VERSION ""

NS_ :

BS_:

BU_: HCU BMS MCU

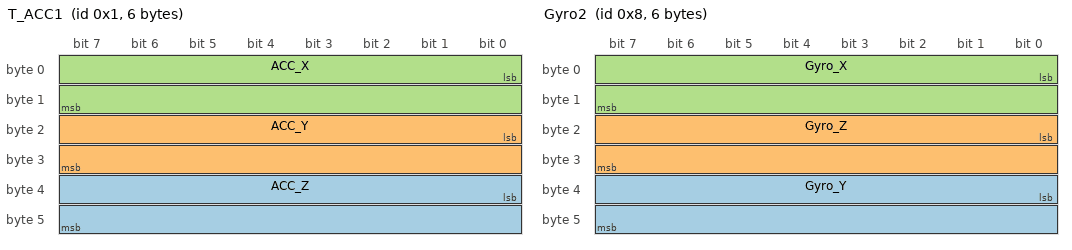
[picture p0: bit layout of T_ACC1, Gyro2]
BO_ 1 T_ACC1: 6 Vector__XXX
 SG_ ACC_Z : 32|16@1- (0.01,-25) [0|0] "g" Vector__XXX
 SG_ ACC_Y : 16|16@1- (0.01,-25) [0|0] "g" Vector__XXX
 SG_ ACC_X : 0|16@1- (0.01,-25) [0|0] "g" Vector__XXX

BO_ 8 Gyro2: 6 Vector__XXX
 SG_ Gyro_Y : 32|16@1- (0.05,-819.15) [0|0] "deg/sec" Vector__XXX
 SG_ Gyro_Z : 16|16@1- (0.05,-819.15) [0|0] "deg/sec" Vector__XXX
 SG_ Gyro_X : 0|16@1- (0.05,-819.15) [0|0] "deg/sec" Vector__XXX

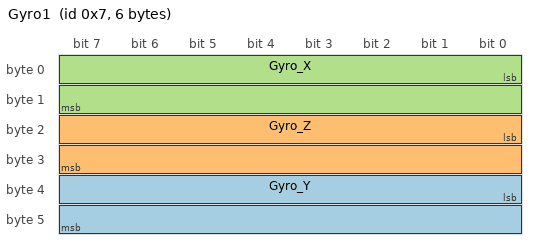
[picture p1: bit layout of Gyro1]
BO_ 7 Gyro1: 6 BMS
 SG_ Gyro_Y : 32|16@1- (0.05,-819.15) [0|0] "deg/sec" Vector__XXX
 SG_ Gyro_Z : 16|16@1- (0.05,-819.15) [0|0] "deg/sec" Vector__XXX
 SG_ Gyro_X : 0|16@1- (0.05,-819.15) [0|0] "deg/sec" Vector__XXX

BA_DEF_ SG_  "GenSigEnvVarType" ENUM  "int","float","undef";
BA_DEF_ SG_  "GenSigSendType" ENUM  "Cyclic","OnWrite","OnWriteWithRepetition","OnChange","OnChangeWithRepetition","IfActive","IfActiveWithRepetition";
BA_DEF_ BO_  "GenMsgDelayTime" INT 1 1000;
BA_DEF_ BO_  "GenMsgCycleTime" INT 2 50000;
BA_DEF_ BO_  "GenMsgSendType" ENUM  "Cyclic","not_used","not_used","not_used","not_used","Cyclic","not_used","IfActive";
BA_DEF_ BO_  "GenMsgCycleTimeFast" INT 2 100000;
BA_DEF_ BO_  "GenMsgILSupport" ENUM  "No","Yes";
BA_DEF_ BU_  "TpNodeBaseAddress" HEX 0 33554431;
BA_DEF_ BU_  "TpUseFC" INT 0 1;
BA_DEF_ BU_  "TpCanBus" INT 1 2;
BA_DEF_ BU_  "TpRxMask" HEX 0 65535;
BA_DEF_ BU_  "TpRxIdentifier" HEX 0 536870911;
BA_DEF_ BU_  "TpTxIdentifier" HEX 0 536870911;
BA_DEF_ BU_  "ILUsed" ENUM  "Yes","No";
BA_DEF_ BU_  "TpAddressingMode" INT 0 3;
BA_DEF_  "GenNWMTalkNM" STRING ;
BA_DEF_  "GenNWMGotoMode_BusSleep" STRING ;
BA_DEF_  "GenNWMGotoMode_Awake" STRING ;
BA_DEF_  "GenNWMApCanSleep" STRING ;
BA_DEF_  "GenNWMApCanOn" STRING ;
BA_DEF_  "GenNWMApCanOff" STRING ;
BA_DEF_  "NmBaseAddress" HEX 1024 1055;
BA_DEF_  "GenEnvVarPrefix" STRING ;
BA_DEF_  "GenEnvVarEndingSnd" STRING ;
BA_DEF_  "GenEnvVarEndingDsp" STRING ;
BA_DEF_  "DBName" STRING ;
BA_DEF_DEF_  "GenSigEnvVarType" "undef";
BA_DEF_DEF_  "GenSigSendType" "Cyclic";
BA_DEF_DEF_  "GenMsgDelayTime" 1;
BA_DEF_DEF_  "GenMsgCycleTime" 2;
BA_DEF_DEF_  "GenMsgSendType" "not_used";
BA_DEF_DEF_  "GenMsgCycleTimeFast" 100;
BA_DEF_DEF_  "GenMsgILSupport" "Yes";
BA_DEF_DEF_  "TpNodeBaseAddress" 1536;
BA_DEF_DEF_  "TpUseFC" 1;
BA_DEF_DEF_  "TpCanBus" 1;
BA_DEF_DEF_  "TpRxMask" 255;
BA_DEF_DEF_  "TpRxIdentifier" 1;
BA_DEF_DEF_  "TpTxIdentifier" 1;
BA_DEF_DEF_  "ILUsed" "Yes";
BA_DEF_DEF_  "TpAddressingMode" 1;
BA_DEF_DEF_  "GenNWMTalkNM" "TalkNM()";
BA_DEF_DEF_  "GenNWMGotoMode_BusSleep" "GotoMode_BusSleep()";
BA_DEF_DEF_  "GenNWMGotoMode_Awake" "GotoMode_Awake()";
BA_DEF_DEF_  "GenNWMApCanSleep" "apCanSleep()";
BA_DEF_DEF_  "GenNWMApCanOn" "apCanOn()";
BA_DEF_DEF_  "GenNWMApCanOff" "apCanOff()";
BA_DEF_DEF_  "NmBaseAddress" 1024;
BA_DEF_DEF_  "GenEnvVarPrefix" "Env";
BA_DEF_DEF_  "GenEnvVarEndingSnd" "_";
BA_DEF_DEF_  "GenEnvVarEndingDsp" "Dsp_";
BA_DEF_DEF_  "DBName" "";
BA_ "DBName" "ACC_CAN";
BA_ "GenMsgCycleTime" BO_ 1 20;
BA_ "GenMsgSendType" BO_ 1 0;
BA_ "GenMsgCycleTime" BO_ 8 10;
BA_ "GenMsgSendType" BO_ 8 0;
BA_ "GenMsgCycleTime" BO_ 7 10;
BA_ "GenMsgSendType" BO_ 7 0;
